AUTOSAR XML (schema 00049)
package /Company/Powertrain/Components
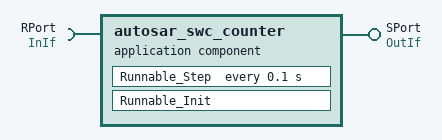
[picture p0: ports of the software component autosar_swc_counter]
  application sw component type autosar_swc_counter
    require port RPort: nonqueued-receiver-com-spec{data-element=InData, alive-timeout=60, init-value=0}, required-interface=InIf
    provide port SPort: nonqueued-sender-com-spec{data-element=OutData, init-value=0}, provided-interface=OutIf
    behavior ASWC_IB: handle-termination-and-restart=NO-SUPPORT
      constant-memorys:
        parameter data prototype INC: category=VALUE, sw-addr-method=VAR, sw-calibration-access=READ-WRITE, type=UInt8_my_qualifier_const, init-value=constant-reference={short-label=INC, constant=INC}
      ar-typed-per-instance-memorys:
        data autosar_swc_co_UnitDelay_DSTATE: category=VALUE, sw-addr-method=VAR, sw-calibration-access=READ-WRITE, type=uint8
      timing event Event_Step: start-on-event=Runnable_Step, period=0.1
      runnable Runnable_Init: sw-addr-method=CODE
      runnable Runnable_Step: sw-addr-method=CODE
        data-read-access:
          access IN_RPort_InData: accessed-variable=RPort.InData
        data-write-access:
          access OUT_SPort_OutData: accessed-variable=SPort.OutData
        parameter access SCALPRM_AMP: accessed-parameter=AMP
      shared-parameters:
        parameter data prototype K: category=VALUE, sw-calibration-access=READ-WRITE, type=uint8, init-value=constant-reference={short-label=K, constant=K}
        parameter data prototype AMP: category=VALUE, sw-addr-method=VAR, sw-calibration-access=READ-WRITE, type=uint8, init-value=constant-reference={short-label=AMP, constant=AMP}
